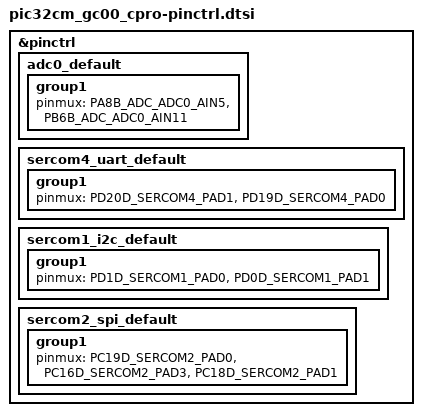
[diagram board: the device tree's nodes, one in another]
/*
 * Copyright (c) 2026 Microchip Technology Inc.
 *
 * SPDX-License-Identifier: Apache-2.0
 */

#include <dt-bindings/pic32c/pic32cm_sg_gc/pic32cm_gc00/pic32cm5112gc00100-pinctrl.h>

&pinctrl {
	adc0_default: adc0_default {
		group1 {
			pinmux = <PA8B_ADC_ADC0_AIN5>,   /* Arduino A0 */
				 <PB6B_ADC_ADC0_AIN11>;  /* VR300 potentiometer */
		};
	};

	sercom4_uart_default: sercom4_uart_default {
		group1 {
			pinmux = <PD20D_SERCOM4_PAD1>,
				 <PD19D_SERCOM4_PAD0>;
		};
	};

	sercom1_i2c_default: sercom1_i2c_default {
		group1 {
			pinmux = <PD1D_SERCOM1_PAD0>,  /* SDA */
				 <PD0D_SERCOM1_PAD1>;  /* SCL */
		};
	};

	sercom2_spi_default: sercom2_spi_default {
		group1 {
			pinmux = <PC19D_SERCOM2_PAD0>,   /* MOSI */
				 <PC16D_SERCOM2_PAD3>,   /* MISO */
				 <PC18D_SERCOM2_PAD1>;   /* SCK  */
		};
	};
};
